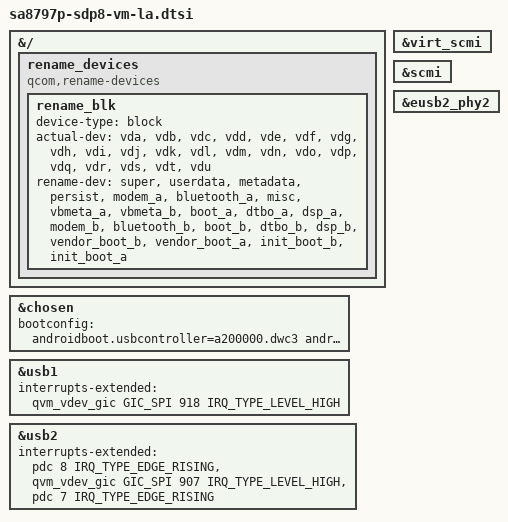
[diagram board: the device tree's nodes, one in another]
&{/} {
	rename_devices: rename_devices {
		compatible = "qcom,rename-devices";
		rename_blk: rename_blk {
			device-type = "block";
			actual-dev = "vda", "vdb", "vdc",
					"vdd", "vde", "vdf",
					"vdg", "vdh", "vdi",
					"vdj", "vdk", "vdl",
					"vdm", "vdn", "vdo",
					"vdp", "vdq", "vdr",
					"vds", "vdt", "vdu";
			rename-dev = "super", "userdata", "metadata",
					"persist", "modem_a","bluetooth_a",
					"misc", "vbmeta_a", "vbmeta_b",
					"boot_a", "dtbo_a", "dsp_a",
					"modem_b", "bluetooth_b", "boot_b",
					"dtbo_b", "dsp_b", "vendor_boot_b",
					"vendor_boot_a", "init_boot_b", "init_boot_a";
		};
	};
};

&chosen {
	bootconfig = "androidboot.usbcontroller=a200000.dwc3 androidboot.dtbo_idx=18";
};

&virt_scmi {
	status = "ok";
};

&scmi {
	status = "ok";
};

&usb1 {
	interrupts-extended = <&qvm_vdev_gic GIC_SPI 918 IRQ_TYPE_LEVEL_HIGH>;
};

&usb2 {
	interrupts-extended = <&pdc 8 IRQ_TYPE_EDGE_RISING>,
			<&qvm_vdev_gic GIC_SPI 907 IRQ_TYPE_LEVEL_HIGH>,
			<&pdc 7 IRQ_TYPE_EDGE_RISING>;
	status = "ok";
};

&eusb2_phy2 {
	status = "ok";
};
